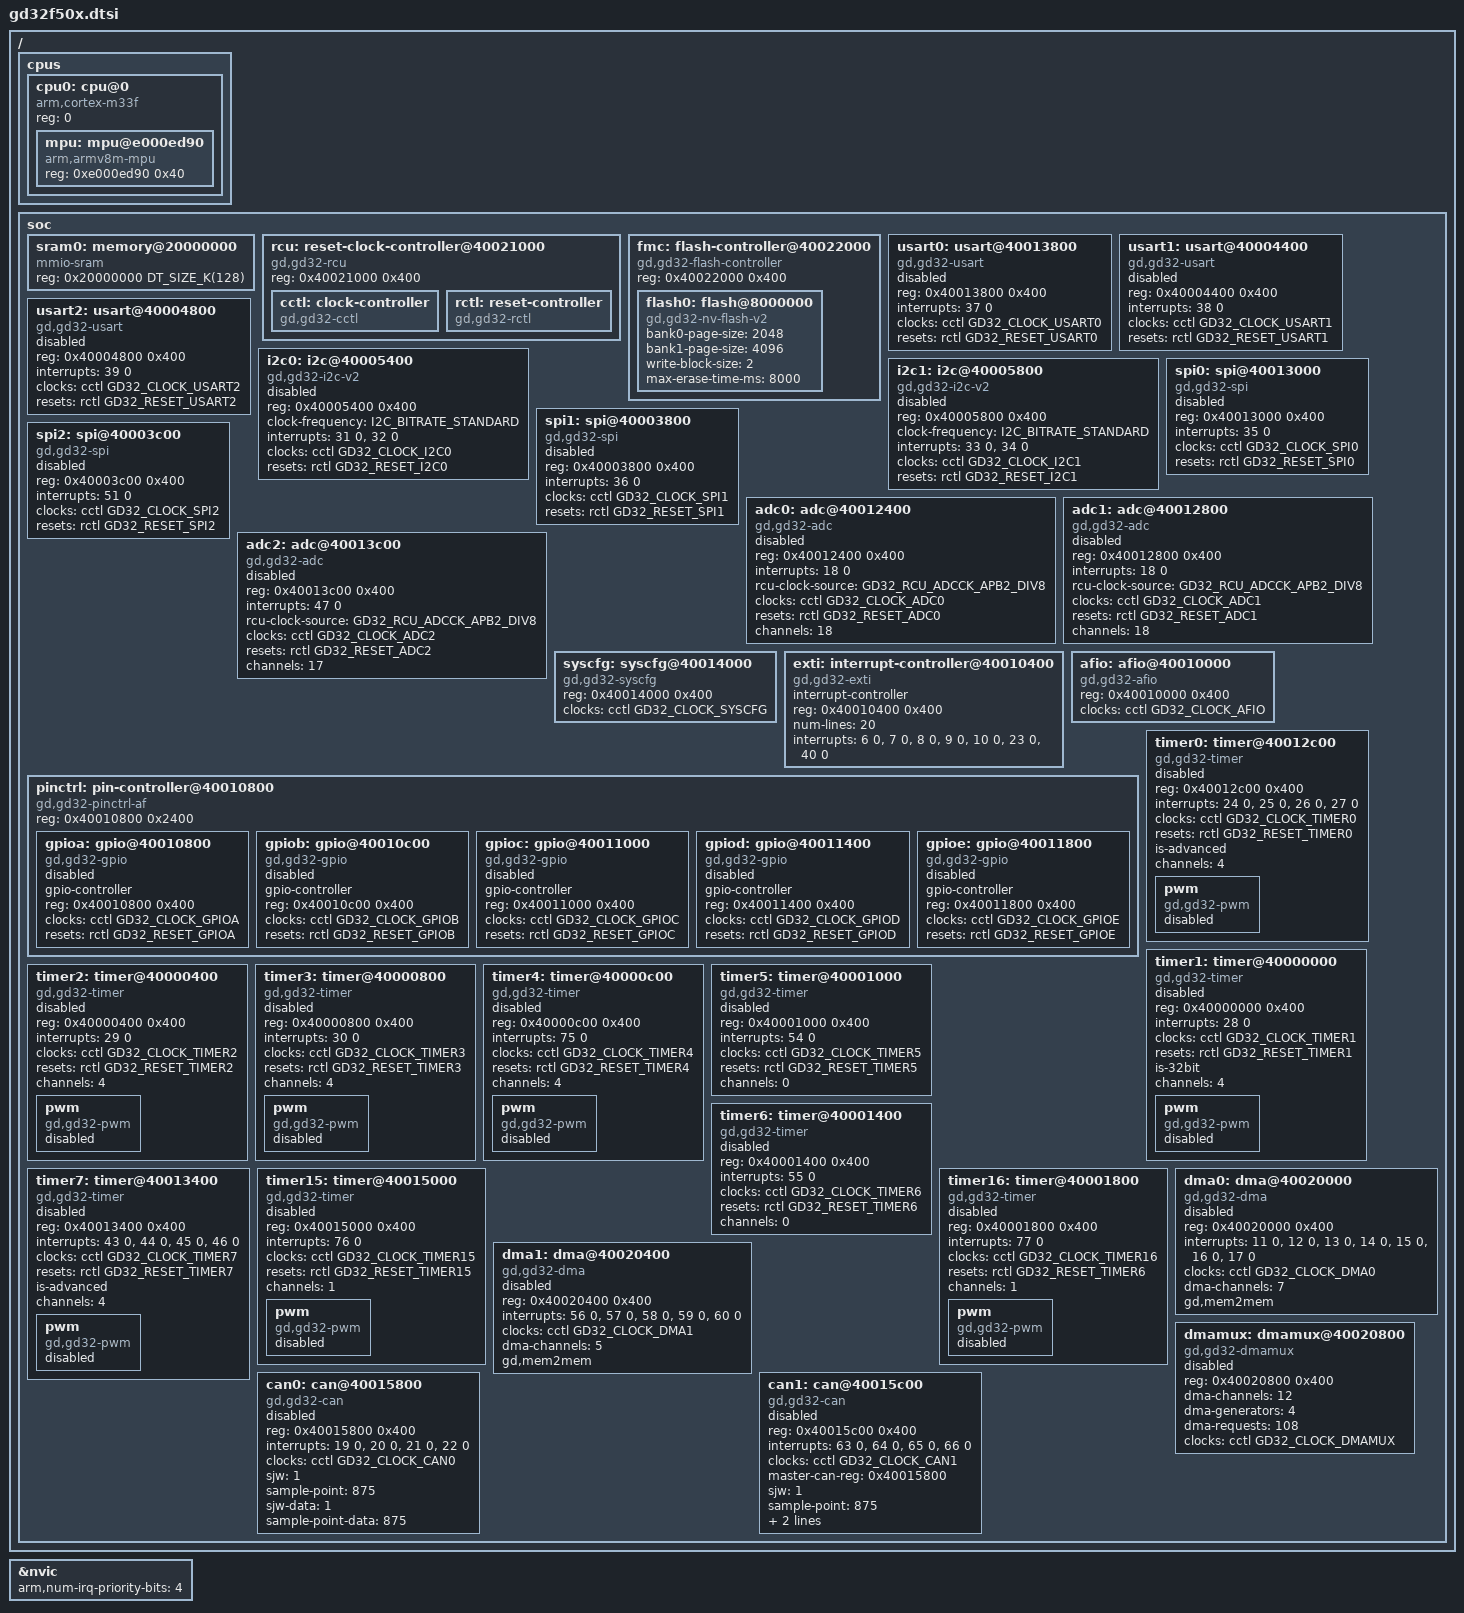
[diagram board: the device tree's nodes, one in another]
/*
 * Copyright (c) 2025 GigaDevice Semiconductor Inc.
 *
 * SPDX-License-Identifier: Apache-2.0
 */

#include <arm/armv8-m.dtsi>
#include <zephyr/dt-bindings/adc/adc.h>
#include <zephyr/dt-bindings/adc/gd32f50x.h>
#include <zephyr/dt-bindings/gpio/gpio.h>
#include <zephyr/dt-bindings/i2c/i2c.h>
#include <zephyr/dt-bindings/pwm/pwm.h>
#include <zephyr/dt-bindings/clock/gd32f50x-clocks.h>
#include <zephyr/dt-bindings/reset/gd32f50x.h>

/ {
	cpus {
		#address-cells = <1>;
		#size-cells = <0>;

		cpu0: cpu@0 {
			compatible = "arm,cortex-m33f";
			reg = <0>;
			#address-cells = <1>;
			#size-cells = <1>;

			mpu: mpu@e000ed90 {
				compatible = "arm,armv8m-mpu";
				reg = <0xe000ed90 0x40>;
			};
		};
	};

	soc {
		sram0: memory@20000000 {
			compatible = "mmio-sram";
			reg = <0x20000000 DT_SIZE_K(128)>;
		};

		rcu: reset-clock-controller@40021000 {
			compatible = "gd,gd32-rcu";
			reg = <0x40021000 0x400>;
			status = "okay";

			cctl: clock-controller {
				compatible = "gd,gd32-cctl";
				#clock-cells = <1>;
				status = "okay";
			};

			rctl: reset-controller {
				compatible = "gd,gd32-rctl";
				#reset-cells = <1>;
				status = "okay";
			};
		};

		fmc: flash-controller@40022000 {
			compatible = "gd,gd32-flash-controller";
			reg = <0x40022000 0x400>;

			#address-cells = <1>;
			#size-cells = <1>;

			flash0: flash@8000000 {
				compatible = "gd,gd32-nv-flash-v2", "soc-nv-flash";
				bank0-page-size = <2048>;
				bank1-page-size = <4096>;
				write-block-size = <2>;
				max-erase-time-ms = <8000>;
			};
		};

		usart0: usart@40013800 {
			compatible = "gd,gd32-usart";
			reg = <0x40013800 0x400>;
			interrupts = <37 0>;
			clocks = <&cctl GD32_CLOCK_USART0>;
			resets = <&rctl GD32_RESET_USART0>;
			status = "disabled";
		};

		usart1: usart@40004400 {
			compatible = "gd,gd32-usart";
			reg = <0x40004400 0x400>;
			interrupts = <38 0>;
			clocks = <&cctl GD32_CLOCK_USART1>;
			resets = <&rctl GD32_RESET_USART1>;
			status = "disabled";
		};

		usart2: usart@40004800 {
			compatible = "gd,gd32-usart";
			reg = <0x40004800 0x400>;
			interrupts = <39 0>;
			clocks = <&cctl GD32_CLOCK_USART2>;
			resets = <&rctl GD32_RESET_USART2>;
			status = "disabled";
		};

		i2c0: i2c@40005400 {
			compatible = "gd,gd32-i2c-v2";
			reg = <0x40005400 0x400>;
			#address-cells = <1>;
			#size-cells = <0>;
			clock-frequency = <I2C_BITRATE_STANDARD>;
			interrupts = <31 0>, <32 0>;
			interrupt-names = "event", "error";
			clocks = <&cctl GD32_CLOCK_I2C0>;
			resets = <&rctl GD32_RESET_I2C0>;
			status = "disabled";
		};

		i2c1: i2c@40005800 {
			compatible = "gd,gd32-i2c-v2";
			reg = <0x40005800 0x400>;
			#address-cells = <1>;
			#size-cells = <0>;
			clock-frequency = <I2C_BITRATE_STANDARD>;
			interrupts = <33 0>, <34 0>;
			interrupt-names = "event", "error";
			clocks = <&cctl GD32_CLOCK_I2C1>;
			resets = <&rctl GD32_RESET_I2C1>;
			status = "disabled";
		};

		spi0: spi@40013000 {
			compatible = "gd,gd32-spi";
			reg = <0x40013000 0x400>;
			interrupts = <35 0>;
			clocks = <&cctl GD32_CLOCK_SPI0>;
			resets = <&rctl GD32_RESET_SPI0>;
			#address-cells = <1>;
			#size-cells = <0>;
			status = "disabled";
		};

		spi1: spi@40003800 {
			compatible = "gd,gd32-spi";
			reg = <0x40003800 0x400>;
			interrupts = <36 0>;
			clocks = <&cctl GD32_CLOCK_SPI1>;
			resets = <&rctl GD32_RESET_SPI1>;
			#address-cells = <1>;
			#size-cells = <0>;
			status = "disabled";
		};

		spi2: spi@40003c00 {
			compatible = "gd,gd32-spi";
			reg = <0x40003c00 0x400>;
			interrupts = <51 0>;
			clocks = <&cctl GD32_CLOCK_SPI2>;
			resets = <&rctl GD32_RESET_SPI2>;
			#address-cells = <1>;
			#size-cells = <0>;
			status = "disabled";
		};

		adc0: adc@40012400 {
			compatible = "gd,gd32-adc";
			reg = <0x40012400 0x400>;
			interrupts = <18 0>;
			rcu-clock-source = <GD32_RCU_ADCCK_APB2_DIV8>;
			clocks = <&cctl GD32_CLOCK_ADC0>;
			resets = <&rctl GD32_RESET_ADC0>;
			channels = <18>;
			status = "disabled";
			#io-channel-cells = <1>;
		};

		adc1: adc@40012800 {
			compatible = "gd,gd32-adc";
			reg = <0x40012800 0x400>;
			interrupts = <18 0>;
			rcu-clock-source = <GD32_RCU_ADCCK_APB2_DIV8>;
			clocks = <&cctl GD32_CLOCK_ADC1>;
			resets = <&rctl GD32_RESET_ADC1>;
			channels = <18>;
			status = "disabled";
			#io-channel-cells = <1>;
		};

		adc2: adc@40013c00 {
			compatible = "gd,gd32-adc";
			reg = <0x40013c00 0x400>;
			interrupts = <47 0>;
			rcu-clock-source = <GD32_RCU_ADCCK_APB2_DIV8>;
			clocks = <&cctl GD32_CLOCK_ADC2>;
			resets = <&rctl GD32_RESET_ADC2>;
			channels = <17>;
			status = "disabled";
			#io-channel-cells = <1>;
		};

		syscfg: syscfg@40014000 {
			compatible = "gd,gd32-syscfg";
			reg = <0x40014000 0x400>;
			clocks = <&cctl GD32_CLOCK_SYSCFG>;
		};

		exti: interrupt-controller@40010400 {
			compatible = "gd,gd32-exti";
			interrupt-controller;
			#interrupt-cells = <1>;
			#address-cells = <0>;
			reg = <0x40010400 0x400>;
			num-lines = <20>;
			interrupts = <6 0>, <7 0>, <8 0>, <9 0>,
				     <10 0>, <23 0>, <40 0>;
			interrupt-names = "line0", "line1", "line2", "line3",
					  "line4", "line5-9", "line10-15";
		};

		afio: afio@40010000 {
			compatible = "gd,gd32-afio";
			reg = <0x40010000 0x400>;
			clocks = <&cctl GD32_CLOCK_AFIO>;
			status = "okay";
		};

		pinctrl: pin-controller@40010800 {
			compatible = "gd,gd32-pinctrl-af";
			reg = <0x40010800 0x2400>;
			#address-cells = <1>;
			#size-cells = <1>;
			status = "okay";

			gpioa: gpio@40010800 {
				compatible = "gd,gd32-gpio";
				gpio-controller;
				#gpio-cells = <2>;
				reg = <0x40010800 0x400>;
				clocks = <&cctl GD32_CLOCK_GPIOA>;
				resets = <&rctl GD32_RESET_GPIOA>;
				status = "disabled";
			};

			gpiob: gpio@40010c00 {
				compatible = "gd,gd32-gpio";
				gpio-controller;
				#gpio-cells = <2>;
				reg = <0x40010c00 0x400>;
				clocks = <&cctl GD32_CLOCK_GPIOB>;
				resets = <&rctl GD32_RESET_GPIOB>;
				status = "disabled";
			};

			gpioc: gpio@40011000 {
				compatible = "gd,gd32-gpio";
				gpio-controller;
				#gpio-cells = <2>;
				reg = <0x40011000 0x400>;
				clocks = <&cctl GD32_CLOCK_GPIOC>;
				resets = <&rctl GD32_RESET_GPIOC>;
				status = "disabled";
			};

			gpiod: gpio@40011400 {
				compatible = "gd,gd32-gpio";
				gpio-controller;
				#gpio-cells = <2>;
				reg = <0x40011400 0x400>;
				clocks = <&cctl GD32_CLOCK_GPIOD>;
				resets = <&rctl GD32_RESET_GPIOD>;
				status = "disabled";
			};

			gpioe: gpio@40011800 {
				compatible = "gd,gd32-gpio";
				gpio-controller;
				#gpio-cells = <2>;
				reg = <0x40011800 0x400>;
				clocks = <&cctl GD32_CLOCK_GPIOE>;
				resets = <&rctl GD32_RESET_GPIOE>;
				status = "disabled";
			};
		};

		timer0: timer@40012c00 {
			compatible = "gd,gd32-timer";
			reg = <0x40012c00 0x400>;
			interrupts = <24 0>, <25 0>, <26 0>, <27 0>;
			interrupt-names = "brk", "up", "trgcom", "cc";
			clocks = <&cctl GD32_CLOCK_TIMER0>;
			resets = <&rctl GD32_RESET_TIMER0>;
			is-advanced;
			channels = <4>;
			status = "disabled";

			pwm {
				compatible = "gd,gd32-pwm";
				status = "disabled";
				#pwm-cells = <3>;
			};
		};

		timer1: timer@40000000 {
			compatible = "gd,gd32-timer";
			reg = <0x40000000 0x400>;
			interrupts = <28 0>;
			interrupt-names = "global";
			clocks = <&cctl GD32_CLOCK_TIMER1>;
			resets = <&rctl GD32_RESET_TIMER1>;
			is-32bit;
			channels = <4>;
			status = "disabled";

			pwm {
				compatible = "gd,gd32-pwm";
				status = "disabled";
				#pwm-cells = <3>;
			};
		};

		timer2: timer@40000400 {
			compatible = "gd,gd32-timer";
			reg = <0x40000400 0x400>;
			interrupts = <29 0>;
			interrupt-names = "global";
			clocks = <&cctl GD32_CLOCK_TIMER2>;
			resets = <&rctl GD32_RESET_TIMER2>;
			channels = <4>;
			status = "disabled";

			pwm {
				compatible = "gd,gd32-pwm";
				status = "disabled";
				#pwm-cells = <3>;
			};
		};

		timer3: timer@40000800 {
			compatible = "gd,gd32-timer";
			reg = <0x40000800 0x400>;
			interrupts = <30 0>;
			interrupt-names = "global";
			clocks = <&cctl GD32_CLOCK_TIMER3>;
			resets = <&rctl GD32_RESET_TIMER3>;
			channels = <4>;
			status = "disabled";

			pwm {
				compatible = "gd,gd32-pwm";
				status = "disabled";
				#pwm-cells = <3>;
			};
		};

		timer4: timer@40000c00 {
			compatible = "gd,gd32-timer";
			reg = <0x40000c00 0x400>;
			interrupts = <75 0>;
			interrupt-names = "global";
			clocks = <&cctl GD32_CLOCK_TIMER4>;
			resets = <&rctl GD32_RESET_TIMER4>;
			channels = <4>;
			status = "disabled";

			pwm {
				compatible = "gd,gd32-pwm";
				status = "disabled";
				#pwm-cells = <3>;
			};
		};

		timer5: timer@40001000 {
			compatible = "gd,gd32-timer";
			reg = <0x40001000 0x400>;
			interrupts = <54 0>;
			interrupt-names = "global";
			clocks = <&cctl GD32_CLOCK_TIMER5>;
			resets = <&rctl GD32_RESET_TIMER5>;
			channels = <0>;
			status = "disabled";
		};

		timer6: timer@40001400 {
			compatible = "gd,gd32-timer";
			reg = <0x40001400 0x400>;
			interrupts = <55 0>;
			interrupt-names = "global";
			clocks = <&cctl GD32_CLOCK_TIMER6>;
			resets = <&rctl GD32_RESET_TIMER6>;
			channels = <0>;
			status = "disabled";
		};

		timer7: timer@40013400 {
			compatible = "gd,gd32-timer";
			reg = <0x40013400 0x400>;
			interrupts = <43 0>, <44 0>, <45 0>, <46 0>;
			interrupt-names = "brk", "up", "trgcom", "cc";
			clocks = <&cctl GD32_CLOCK_TIMER7>;
			resets = <&rctl GD32_RESET_TIMER7>;
			is-advanced;
			channels = <4>;
			status = "disabled";

			pwm {
				compatible = "gd,gd32-pwm";
				status = "disabled";
				#pwm-cells = <3>;
			};
		};

		timer15: timer@40015000 {
			compatible = "gd,gd32-timer";
			reg = <0x40015000 0x400>;
			interrupts = <76 0>;
			interrupt-names = "global";
			clocks = <&cctl GD32_CLOCK_TIMER15>;
			resets = <&rctl GD32_RESET_TIMER15>;
			channels = <1>;
			status = "disabled";

			pwm {
				compatible = "gd,gd32-pwm";
				status = "disabled";
				#pwm-cells = <3>;
			};
		};

		timer16: timer@40001800 {
			compatible = "gd,gd32-timer";
			reg = <0x40001800 0x400>;
			interrupts = <77 0>;
			interrupt-names = "global";
			clocks = <&cctl GD32_CLOCK_TIMER16>;
			/* No separate RESET_TIMER16 in the binding �� TIMER16
			 * shares its APB1 reset bit with TIMER6. Using
			 * GD32_RESET_TIMER5 as a placeholder is a stop-gap
			 * until the binding file is extended.
			 */
			resets = <&rctl GD32_RESET_TIMER6>;
			channels = <1>;
			status = "disabled";

			pwm {
				compatible = "gd,gd32-pwm";
				status = "disabled";
				#pwm-cells = <3>;
			};
		};

		dma0: dma@40020000 {
			compatible = "gd,gd32-dma";
			reg = <0x40020000 0x400>;
			interrupts = <11 0>, <12 0>, <13 0>, <14 0>,
				     <15 0>, <16 0>, <17 0>;
			clocks = <&cctl GD32_CLOCK_DMA0>;
			dma-channels = <7>;
			gd,mem2mem;
			#dma-cells = <2>;
			status = "disabled";
		};

		dma1: dma@40020400 {
			compatible = "gd,gd32-dma";
			reg = <0x40020400 0x400>;
			interrupts = <56 0>, <57 0>, <58 0>, <59 0>, <60 0>;
			clocks = <&cctl GD32_CLOCK_DMA1>;
			dma-channels = <5>;
			gd,mem2mem;
			#dma-cells = <2>;
			status = "disabled";
		};

		dmamux: dmamux@40020800 {
			compatible = "gd,gd32-dmamux";
			reg = <0x40020800 0x400>;
			#dma-cells = <3>;
			dma-channels = <12>;
			dma-generators = <4>;
			dma-requests = <108>;
			clocks = <&cctl GD32_CLOCK_DMAMUX>;
			status = "disabled";
		};

		can0: can@40015800 {
			compatible = "gd,gd32-can";
			reg = <0x40015800 0x400>;
			interrupts = <19 0>, <20 0>, <21 0>, <22 0>;
			interrupt-names = "TX", "RX0", "RX1", "SCE";
			clocks = <&cctl GD32_CLOCK_CAN0>;
			status = "disabled";
			sjw = <1>;
			sample-point = <875>;
			sjw-data = <1>;
			sample-point-data = <875>;
		};

		can1: can@40015c00 {
			compatible = "gd,gd32-can";
			reg = <0x40015c00 0x400>;
			interrupts = <63 0>, <64 0>, <65 0>, <66 0>;
			interrupt-names = "TX", "RX0", "RX1", "SCE";
			clocks = <&cctl GD32_CLOCK_CAN1>;
			master-can-reg = <0x40015800>;
			status = "disabled";
			sjw = <1>;
			sample-point = <875>;
			sjw-data = <1>;
			sample-point-data = <875>;
		};
	};
};

&nvic {
	arm,num-irq-priority-bits = <4>;
};
